# AST1080 register map
File version: 1.0
CPU: CM4 r0p1, little endian, MPU, FPU, 4 interrupt priority bits, 256 interrupts
Registers are 32-bit, read-write, reset 0x0 unless marked. A register's access mark holds for its fields unless they carry their own. Offsets are from the block's base; [hi:lo] are bit positions; {n}, {i} and the like mark numbered series; 'fields as' and 'values as' point back to an identical list.

## gpio (part 1 of 2)
Base 0x74C0B000
0x00 GPIO000 — Debounce Timer Setting Register \#1
  [23:0] DebounceTimerValue
0x04 GPIO004 — Debounce Timer Setting Register \#2
  [23:0] DebounceTimerValue1 — Debounce Timer Value
0x08 GPIO008 — Debounce Timer Setting Register \#3
  [23:0] DebounceTimerValue2 — Debounce Timer Value
0x0C GPIO00C — GPIO Blink Source Clock Division
  [23:0] BlinkSourceClkDivisionOnlyEffectiveToPCLKAsSrcClk — Blink Source Clock Division. Only effective to PCLK as source clock
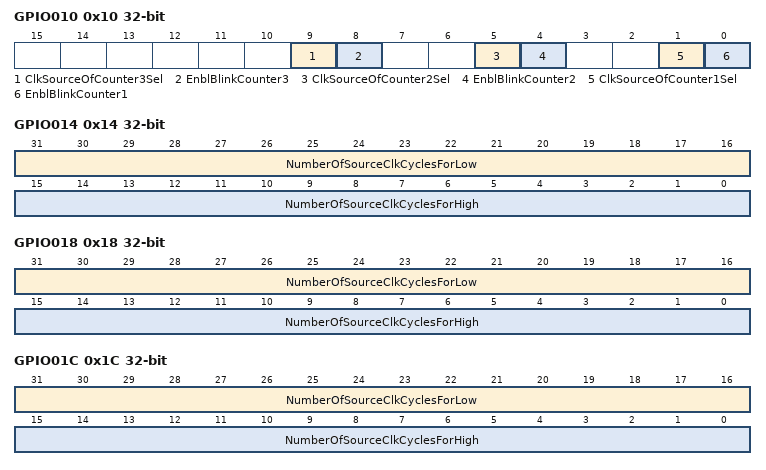
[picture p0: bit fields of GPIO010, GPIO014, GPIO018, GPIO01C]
0x10 GPIO010 — GPIO Blink Control
  [9] ClkSourceOfCounter3Sel — Clock Source of Counter #3 Selection
    0=Choose_PCLKhlinkGPIO00C1_As_Source_Clock; 1=Choose_CLK1M_As_Source_Clock
  [8] EnblBlinkCounter3 — Enable Blink Counter #3
  [5] ClkSourceOfCounter2Sel — Clock Source of Counter #2 Selection
    values as ClkSourceOfCounter3Sel
  [4] EnblBlinkCounter2 — Enable Blink Counter #2
  [1] ClkSourceOfCounter1Sel — Clock Source of Counter #1 Selection
    values as ClkSourceOfCounter3Sel
  [0] EnblBlinkCounter1 — Enable Blink Counter #1
0x14 GPIO014 — GPIO Blink Counter \#1 Configuration
  [31:16] NumberOfSourceClkCyclesForLow — Number of Source Clock cycles for Low
  [15:0] NumberOfSourceClkCyclesForHigh — Number of Source Clock cycles for High
0x18 GPIO018 — GPIO Blink Counter \#2 Configuration
  fields as GPIO014
0x1C GPIO01C — GPIO Blink Counter \#3 Configuration
  fields as GPIO014
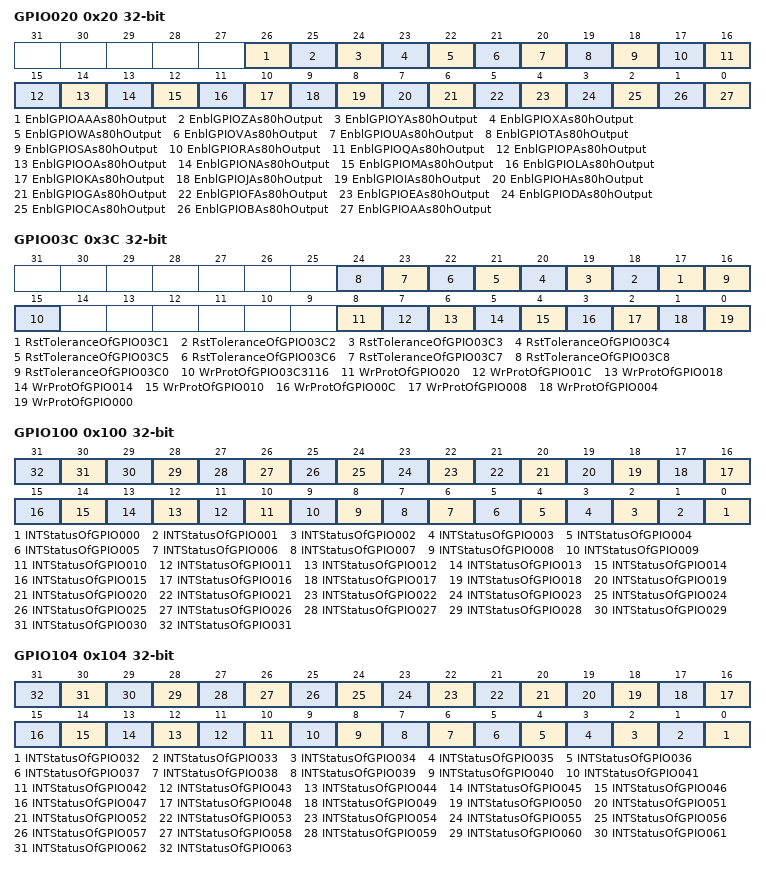
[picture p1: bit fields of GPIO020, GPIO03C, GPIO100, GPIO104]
0x20 GPIO020 — 80h Enable Register
  [26] EnblGPIOAAAs80hOutput — Enable GPIOAA as 80h output
  [25] EnblGPIOZAs80hOutput — Enable GPIOZ as 80h output
  [24] EnblGPIOYAs80hOutput — Enable GPIOY as 80h output
  [23] EnblGPIOXAs80hOutput — Enable GPIOX as 80h output
  [22] EnblGPIOWAs80hOutput — Enable GPIOW as 80h output
  [21] EnblGPIOVAs80hOutput — Enable GPIOV as 80h output
  [20] EnblGPIOUAs80hOutput — Enable GPIOU as 80h output
  [19] EnblGPIOTAs80hOutput — Enable GPIOT as 80h output
  [18] EnblGPIOSAs80hOutput — Enable GPIOS as 80h output
  [17] EnblGPIORAs80hOutput — Enable GPIOR as 80h output
  [16] EnblGPIOQAs80hOutput — Enable GPIOQ as 80h output
  [15] EnblGPIOPAs80hOutput — Enable GPIOP as 80h output
  [14] EnblGPIOOAs80hOutput — Enable GPIOO as 80h output
  [13] EnblGPIONAs80hOutput — Enable GPION as 80h output
  [12] EnblGPIOMAs80hOutput — Enable GPIOM as 80h output
  [11] EnblGPIOLAs80hOutput — Enable GPIOL as 80h output
  [10] EnblGPIOKAs80hOutput — Enable GPIOK as 80h output
  [9] EnblGPIOJAs80hOutput — Enable GPIOJ as 80h output
  [8] EnblGPIOIAs80hOutput — Enable GPIOI as 80h output
  [7] EnblGPIOHAs80hOutput — Enable GPIOH as 80h output
  [6] EnblGPIOGAs80hOutput — Enable GPIOG as 80h output
  [5] EnblGPIOFAs80hOutput — Enable GPIOF as 80h output
  [4] EnblGPIOEAs80hOutput — Enable GPIOE as 80h output
  [3] EnblGPIODAs80hOutput — Enable GPIOD as 80h output
  [2] EnblGPIOCAs80hOutput — Enable GPIOC as 80h output
  [1] EnblGPIOBAs80hOutput — Enable GPIOB as 80h output
  [0] EnblGPIOAAs80hOutput — Enable GPIOA as 80h output
0x3C GPIO03C — Write Protection Register
  [n+16] RstToleranceOfGPIO03C{n} (n=1..8) — Reset Tolerance of GPIO03C[{n}]
  [16] RstToleranceOfGPIO03C0 — Reset Tolerance of GPIO03C[0]
    0=SRST; 1=WDT_Reset
  [15] WrProtOfGPIO03C3116 — Write Protection of GPIO03C[31:16]
  [8] WrProtOfGPIO020 — Write Protection of GPIO020
  [7] WrProtOfGPIO01C — Write Protection of GPIO01C
  [6] WrProtOfGPIO018 — Write Protection of GPIO018
  [5] WrProtOfGPIO014 — Write Protection of GPIO014
  [4] WrProtOfGPIO010 — Write Protection of GPIO010
  [3] WrProtOfGPIO00C — Write Protection of GPIO00C
  [2] WrProtOfGPIO008 — Write Protection of GPIO008
  [1] WrProtOfGPIO004 — Write Protection of GPIO004
  [0] WrProtOfGPIO000 — Write Protection of GPIO000
0x100 GPIO100 — Interrupt Status Register \#1
  [n] INTStatusOfGPIO{n:03} ro (n=0..31) — Interrupt Status of GPIO{n:03}
0x104 GPIO104 — Interrupt Status Register \#2
  [n-32] INTStatusOfGPIO{n:03} ro (n=32..63) — Interrupt Status of GPIO{n:03}
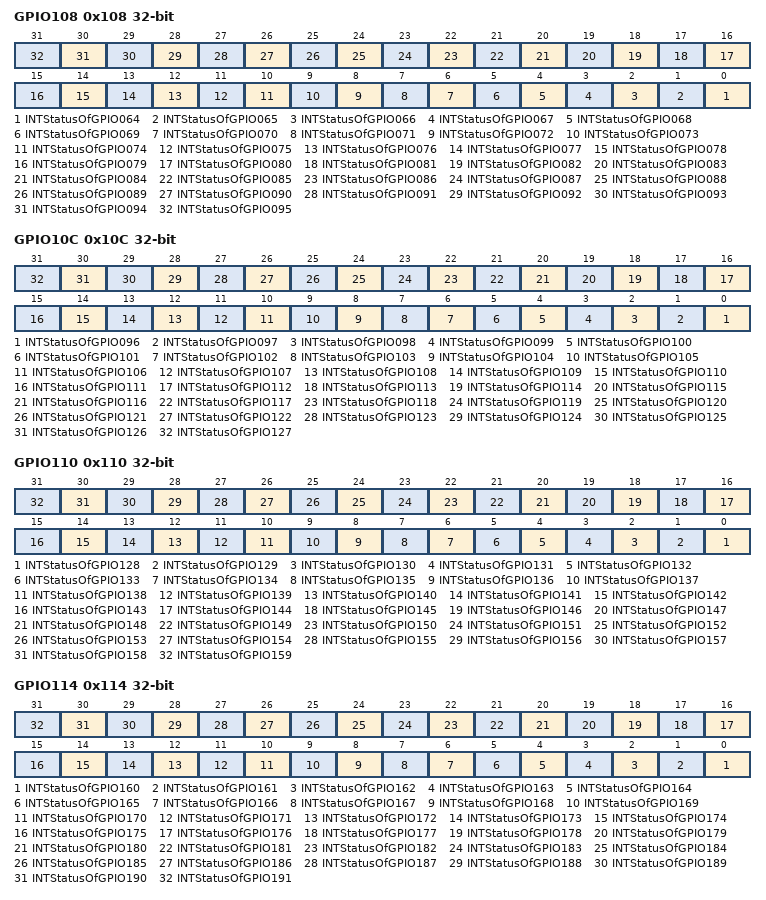
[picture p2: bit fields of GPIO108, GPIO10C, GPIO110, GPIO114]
0x108 GPIO108 — Interrupt Status Register \#3
  [n-64] INTStatusOfGPIO{n:03} ro (n=64..95) — Interrupt Status of GPIO{n:03}
0x10C GPIO10C — Interrupt Status Register \#4
  [n-96] INTStatusOfGPIO{n:03} ro (n=96..127) — Interrupt Status of GPIO{n:03}
0x110 GPIO110 — Interrupt Status Register \#5
  [n-128] INTStatusOfGPIO{n} ro (n=128..159) — Interrupt Status of GPIO{n}
0x114 GPIO114 — Interrupt Status Register \#6
  [n-160] INTStatusOfGPIO{n} ro (n=160..191) — Interrupt Status of GPIO{n}
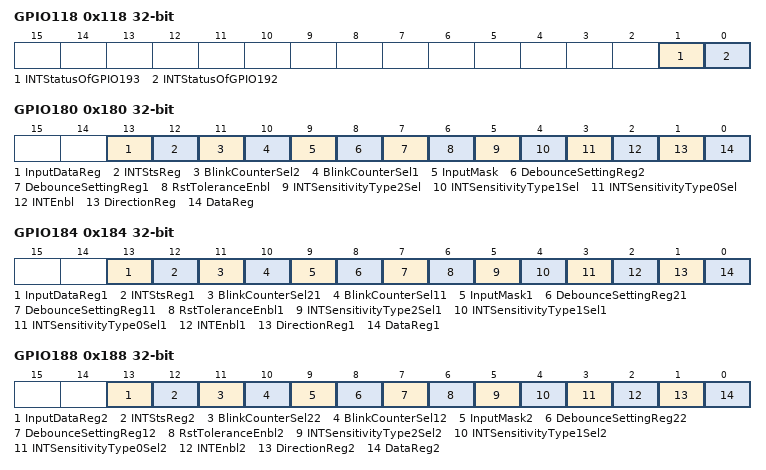
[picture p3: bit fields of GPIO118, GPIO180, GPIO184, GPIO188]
0x118 GPIO118 — Interrupt Status Register \#7
  [1] INTStatusOfGPIO193 ro — Interrupt Status of GPIO193
  [0] INTStatusOfGPIO192 ro — Interrupt Status of GPIO192
0x180 GPIO180 — GPIO000 Control Register
  [13] InputDataReg ro — Input data register
  [12] INTStsReg — Interrupt status register
    0=No_Interrupt_Pending; 1=Interrupt_Pending
  [11] BlinkCounterSel2 — Blink Counter Selection #2
  [10] BlinkCounterSel1 — Blink Counter Selection #1
  [9] InputMask
    0=Read_From_Bit13_Will_Be_Updated; 1=Read_From_Bit13_Will_Not_Be_Updated
  [8] DebounceSettingReg2 — Debounce setting register #2
  [7] DebounceSettingReg1 — Debounce setting register #1
  [6] RstToleranceEnbl — Reset tolerance enable
    0=Bit0_And_Bit1_Will_Be_Reset_By_WDTSOC_Andor_EXTRSTN_Reset; 1=Bit0_And_Bit1_Will_Not_Be_Reset_By_WDTSOC_Andor_EXTRSTN
  [5] INTSensitivityType2Sel — Interrupt sensitivity type 2 selection
    0=Select_Edge_Or_Level_Trigger_Mode; 1=Select_Dualedge_Trigger_Mode
  [4] INTSensitivityType1Sel — Interrupt sensitivity type 1 selection
    0=Select_Edge_Trigger_Mode; 1=Select_Level_Trigger_Mode
  [3] INTSensitivityType0Sel — Interrupt sensitivity type 0 selection
    0=Select_Fallingedge_Or_Levellow_Trigger_Mode; 1=Select_Risingedge_Or_Levelhigh_Trigger_Mode
  [2] INTEnbl — Interrupt enable
    0=Disable_Interrupt; 1=Enable_Interrupt
  [1] DirectionReg — Direction register
    0=Input; 1=Output
  [0] DataReg — Data register
    0=Output_0_If_Bit1_Is_1; 1=Output_1_If_Bit1_Is_1
0x184 GPIO184 — GPIO001 Control Register
  [13] InputDataReg1 ro — Input data register
  [12] INTStsReg1 — Interrupt status register
    0=No_Interrupt_Pending; 1=Interrupt_Pending
  [11] BlinkCounterSel21 — Blink Counter Selection #2
  [10] BlinkCounterSel11 — Blink Counter Selection #1
  [9] InputMask1 — Input mask
    values as GPIO180.InputMask
  [8] DebounceSettingReg21 — Debounce setting register #2
  [7] DebounceSettingReg11 — Debounce setting register #1
  [6] RstToleranceEnbl1 — Reset tolerance enable
    values as GPIO180.RstToleranceEnbl
  [5] INTSensitivityType2Sel1 — Interrupt sensitivity type 2 selection
    values as GPIO180.INTSensitivityType2Sel
  [4] INTSensitivityType1Sel1 — Interrupt sensitivity type 1 selection
    0=Select_Edge_Trigger_Mode; 1=Select_Level_Trigger_Mode
  [3] INTSensitivityType0Sel1 — Interrupt sensitivity type 0 selection
    values as GPIO180.INTSensitivityType0Sel
  [2] INTEnbl1 — Interrupt enable
    0=Disable_Interrupt; 1=Enable_Interrupt
  [1] DirectionReg1 — Direction register
    0=Input; 1=Output
  [0] DataReg1 — Data register
    0=Output_0_If_Bit1_Is_1; 1=Output_1_If_Bit1_Is_1
0x188 GPIO188 — GPIO002 Control Register
  [13] InputDataReg2 ro — Input data register
  [12] INTStsReg2 — Interrupt status register
    0=No_Interrupt_Pending; 1=Interrupt_Pending
  [11] BlinkCounterSel22 — Blink Counter Selection #2
  [10] BlinkCounterSel12 — Blink Counter Selection #1
  [9] InputMask2 — Input mask
    values as GPIO180.InputMask
  [8] DebounceSettingReg22 — Debounce setting register #2
  [7] DebounceSettingReg12 — Debounce setting register #1
  [6] RstToleranceEnbl2 — Reset tolerance enable
    values as GPIO180.RstToleranceEnbl
  [5] INTSensitivityType2Sel2 — Interrupt sensitivity type 2 selection
    values as GPIO180.INTSensitivityType2Sel
  [4] INTSensitivityType1Sel2 — Interrupt sensitivity type 1 selection
    0=Select_Edge_Trigger_Mode; 1=Select_Level_Trigger_Mode
  [3] INTSensitivityType0Sel2 — Interrupt sensitivity type 0 selection
    values as GPIO180.INTSensitivityType0Sel
  [2] INTEnbl2 — Interrupt enable
    0=Disable_Interrupt; 1=Enable_Interrupt
  [1] DirectionReg2 — Direction register
    0=Input; 1=Output
  [0] DataReg2 — Data register
    0=Output_0_If_Bit1_Is_1; 1=Output_1_If_Bit1_Is_1
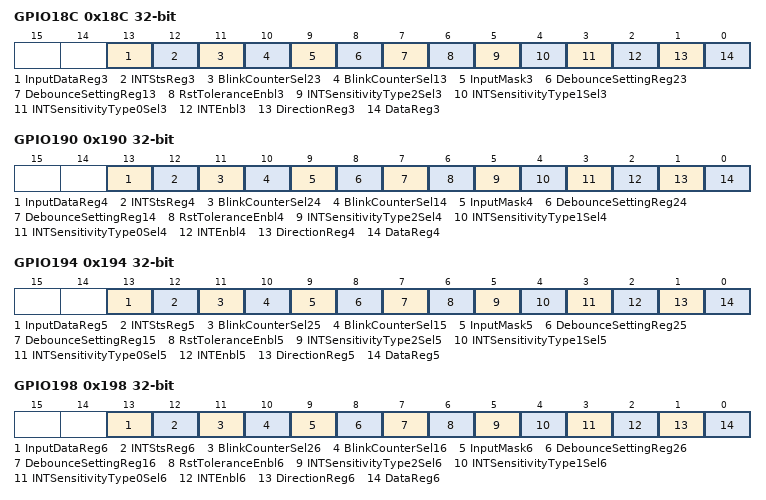
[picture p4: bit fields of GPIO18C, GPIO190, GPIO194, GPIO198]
0x18C GPIO18C — GPIO003 Control Register
  [13] InputDataReg3 ro — Input data register
  [12] INTStsReg3 — Interrupt status register
    0=No_Interrupt_Pending; 1=Interrupt_Pending
  [11] BlinkCounterSel23 — Blink Counter Selection #2
  [10] BlinkCounterSel13 — Blink Counter Selection #1
  [9] InputMask3 — Input mask
    values as GPIO180.InputMask
  [8] DebounceSettingReg23 — Debounce setting register #2
  [7] DebounceSettingReg13 — Debounce setting register #1
  [6] RstToleranceEnbl3 — Reset tolerance enable
    values as GPIO180.RstToleranceEnbl
  [5] INTSensitivityType2Sel3 — Interrupt sensitivity type 2 selection
    values as GPIO180.INTSensitivityType2Sel
  [4] INTSensitivityType1Sel3 — Interrupt sensitivity type 1 selection
    0=Select_Edge_Trigger_Mode; 1=Select_Level_Trigger_Mode
  [3] INTSensitivityType0Sel3 — Interrupt sensitivity type 0 selection
    values as GPIO180.INTSensitivityType0Sel
  [2] INTEnbl3 — Interrupt enable
    0=Disable_Interrupt; 1=Enable_Interrupt
  [1] DirectionReg3 — Direction register
    0=Input; 1=Output
  [0] DataReg3 — Data register
    0=Output_0_If_Bit1_Is_1; 1=Output_1_If_Bit1_Is_1
0x190 GPIO190 — GPIO004 Control Register
  [13] InputDataReg4 ro — Input data register
  [12] INTStsReg4 — Interrupt status register
    0=No_Interrupt_Pending; 1=Interrupt_Pending
  [11] BlinkCounterSel24 — Blink Counter Selection #2
  [10] BlinkCounterSel14 — Blink Counter Selection #1
  [9] InputMask4 — Input mask
    values as GPIO180.InputMask
  [8] DebounceSettingReg24 — Debounce setting register #2
  [7] DebounceSettingReg14 — Debounce setting register #1
  [6] RstToleranceEnbl4 — Reset tolerance enable
    values as GPIO180.RstToleranceEnbl
  [5] INTSensitivityType2Sel4 — Interrupt sensitivity type 2 selection
    values as GPIO180.INTSensitivityType2Sel
  [4] INTSensitivityType1Sel4 — Interrupt sensitivity type 1 selection
    0=Select_Edge_Trigger_Mode; 1=Select_Level_Trigger_Mode
  [3] INTSensitivityType0Sel4 — Interrupt sensitivity type 0 selection
    values as GPIO180.INTSensitivityType0Sel
  [2] INTEnbl4 — Interrupt enable
    0=Disable_Interrupt; 1=Enable_Interrupt
  [1] DirectionReg4 — Direction register
    0=Input; 1=Output
  [0] DataReg4 — Data register
    0=Output_0_If_Bit1_Is_1; 1=Output_1_If_Bit1_Is_1
0x194 GPIO194 — GPIO005 Control Register
  [13] InputDataReg5 ro — Input data register
  [12] INTStsReg5 — Interrupt status register
    0=No_Interrupt_Pending; 1=Interrupt_Pending
  [11] BlinkCounterSel25 — Blink Counter Selection #2
  [10] BlinkCounterSel15 — Blink Counter Selection #1
  [9] InputMask5 — Input mask
    values as GPIO180.InputMask
  [8] DebounceSettingReg25 — Debounce setting register #2
  [7] DebounceSettingReg15 — Debounce setting register #1
  [6] RstToleranceEnbl5 — Reset tolerance enable
    values as GPIO180.RstToleranceEnbl
  [5] INTSensitivityType2Sel5 — Interrupt sensitivity type 2 selection
    values as GPIO180.INTSensitivityType2Sel
  [4] INTSensitivityType1Sel5 — Interrupt sensitivity type 1 selection
    0=Select_Edge_Trigger_Mode; 1=Select_Level_Trigger_Mode
  [3] INTSensitivityType0Sel5 — Interrupt sensitivity type 0 selection
    values as GPIO180.INTSensitivityType0Sel
  [2] INTEnbl5 — Interrupt enable
    0=Disable_Interrupt; 1=Enable_Interrupt
  [1] DirectionReg5 — Direction register
    0=Input; 1=Output
  [0] DataReg5 — Data register
    0=Output_0_If_Bit1_Is_1; 1=Output_1_If_Bit1_Is_1
0x198 GPIO198 — GPIO006 Control Register
  [13] InputDataReg6 ro — Input data register
  [12] INTStsReg6 — Interrupt status register
    0=No_Interrupt_Pending; 1=Interrupt_Pending
  [11] BlinkCounterSel26 — Blink Counter Selection #2
  [10] BlinkCounterSel16 — Blink Counter Selection #1
  [9] InputMask6 — Input mask
    values as GPIO180.InputMask
  [8] DebounceSettingReg26 — Debounce setting register #2
  [7] DebounceSettingReg16 — Debounce setting register #1
  [6] RstToleranceEnbl6 — Reset tolerance enable
    values as GPIO180.RstToleranceEnbl
  [5] INTSensitivityType2Sel6 — Interrupt sensitivity type 2 selection
    values as GPIO180.INTSensitivityType2Sel
  [4] INTSensitivityType1Sel6 — Interrupt sensitivity type 1 selection
    0=Select_Edge_Trigger_Mode; 1=Select_Level_Trigger_Mode
  [3] INTSensitivityType0Sel6 — Interrupt sensitivity type 0 selection
    values as GPIO180.INTSensitivityType0Sel
  [2] INTEnbl6 — Interrupt enable
    0=Disable_Interrupt; 1=Enable_Interrupt
  [1] DirectionReg6 — Direction register
    0=Input; 1=Output
  [0] DataReg6 — Data register
    0=Output_0_If_Bit1_Is_1; 1=Output_1_If_Bit1_Is_1
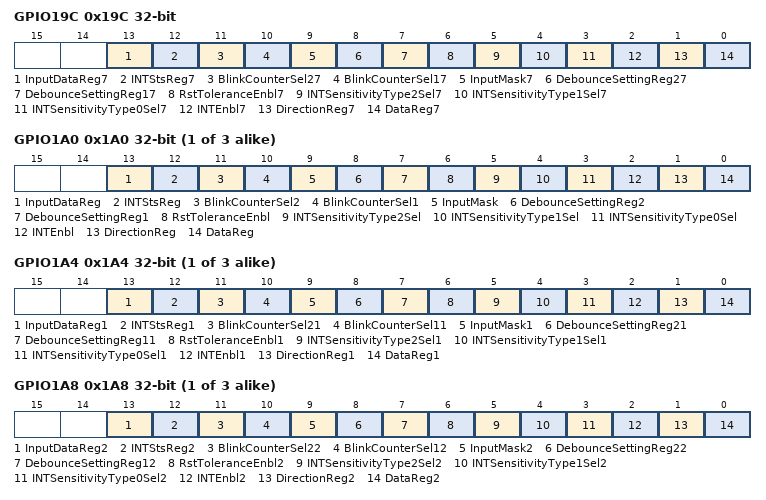
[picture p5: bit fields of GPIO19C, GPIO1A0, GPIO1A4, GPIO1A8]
0x19C GPIO19C — GPIO007 Control Register
  [13] InputDataReg7 ro — Input data register
  [12] INTStsReg7 — Interrupt status register
    0=No_Interrupt_Pending; 1=Interrupt_Pending
  [11] BlinkCounterSel27 — Blink Counter Selection #2
  [10] BlinkCounterSel17 — Blink Counter Selection #1
  [9] InputMask7 — Input mask
    values as GPIO180.InputMask
  [8] DebounceSettingReg27 — Debounce setting register #2
  [7] DebounceSettingReg17 — Debounce setting register #1
  [6] RstToleranceEnbl7 — Reset tolerance enable
    values as GPIO180.RstToleranceEnbl
  [5] INTSensitivityType2Sel7 — Interrupt sensitivity type 2 selection
    values as GPIO180.INTSensitivityType2Sel
  [4] INTSensitivityType1Sel7 — Interrupt sensitivity type 1 selection
    0=Select_Edge_Trigger_Mode; 1=Select_Level_Trigger_Mode
  [3] INTSensitivityType0Sel7 — Interrupt sensitivity type 0 selection
    values as GPIO180.INTSensitivityType0Sel
  [2] INTEnbl7 — Interrupt enable
    0=Disable_Interrupt; 1=Enable_Interrupt
  [1] DirectionReg7 — Direction register
    0=Input; 1=Output
  [0] DataReg7 — Data register
    0=Output_0_If_Bit1_Is_1; 1=Output_1_If_Bit1_Is_1
{0xA0+0x100*i} GPIO{i}A0 (i=1..3) — GPIO{64i-56:03} Control Register
  fields as GPIO180
{0xA4+0x100*i} GPIO{i}A4 (i=1..3) — GPIO{64i-55:03} Control Register
  fields as GPIO184
{0xA8+0x100*i} GPIO{i}A8 (i=1..3) — GPIO{64i-54:03} Control Register
  fields as GPIO188
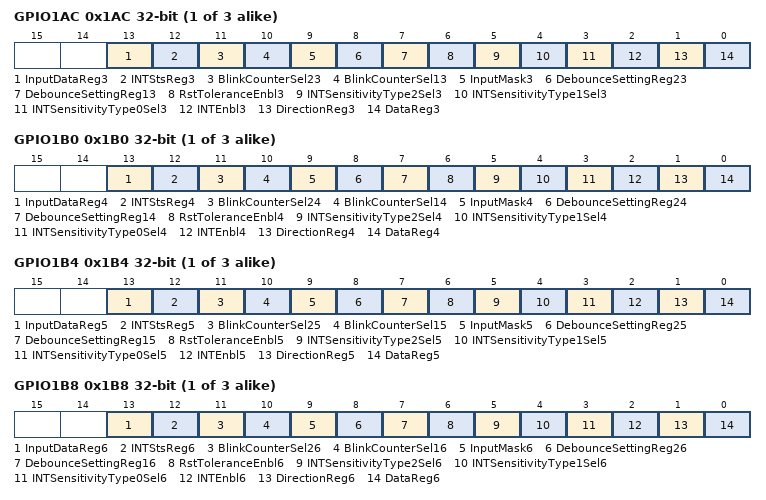
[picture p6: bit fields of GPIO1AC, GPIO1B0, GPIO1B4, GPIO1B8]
{0xAC+0x100*i} GPIO{i}AC (i=1..3) — GPIO{64i-53:03} Control Register
  fields as GPIO18C
{0xB0+0x100*i} GPIO{i}B0 (i=1..3) — GPIO{64i-52:03} Control Register
  fields as GPIO190
{0xB4+0x100*i} GPIO{i}B4 (i=1..3) — GPIO{64i-51:03} Control Register
  fields as GPIO194
{0xB8+0x100*i} GPIO{i}B8 (i=1..3) — GPIO{64i-50:03} Control Register
  fields as GPIO198
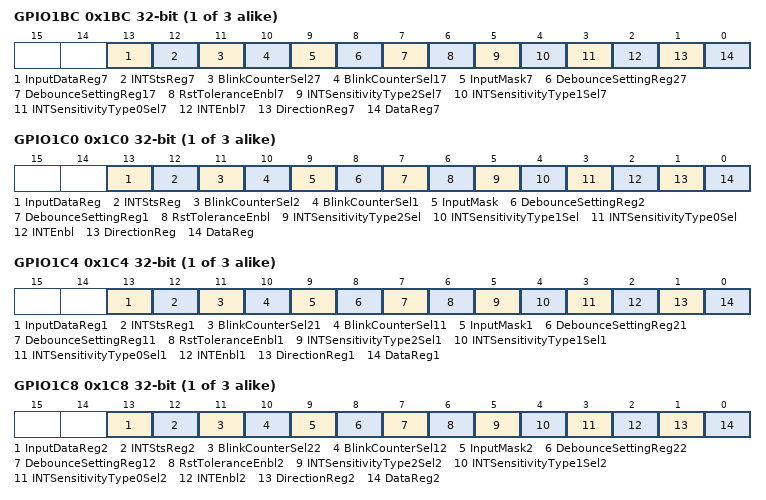
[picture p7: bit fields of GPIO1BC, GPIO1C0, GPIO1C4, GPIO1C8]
{0xBC+0x100*i} GPIO{i}BC (i=1..3) — GPIO{64i-49:03} Control Register
  fields as GPIO19C
{0xC0+0x100*i} GPIO{i}C0 (i=1..3) — GPIO{64i-48:03} Control Register
  fields as GPIO180
{0xC4+0x100*i} GPIO{i}C4 (i=1..3) — GPIO{64i-47:03} Control Register
  fields as GPIO184
{0xC8+0x100*i} GPIO{i}C8 (i=1..3) — GPIO{64i-46:03} Control Register
  fields as GPIO188
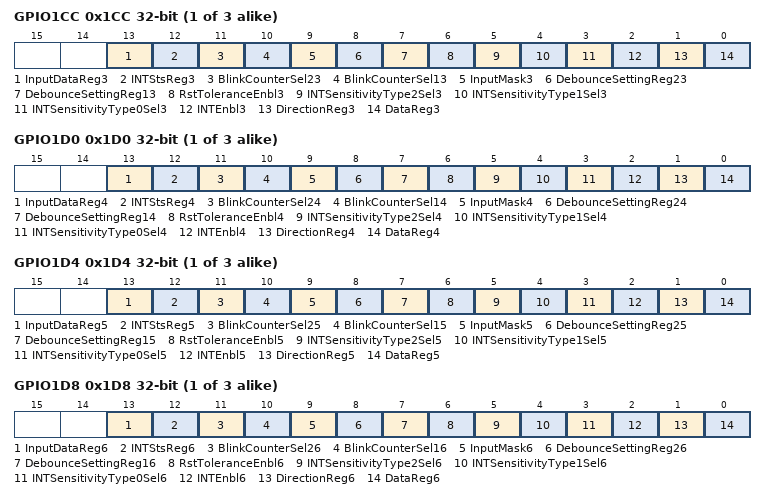
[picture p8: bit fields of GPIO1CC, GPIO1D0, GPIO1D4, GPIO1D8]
{0xCC+0x100*i} GPIO{i}CC (i=1..3) — GPIO{64i-45:03} Control Register
  fields as GPIO18C
{0xD0+0x100*i} GPIO{i}D0 (i=1..3) — GPIO{64i-44:03} Control Register
  fields as GPIO190
{0xD4+0x100*i} GPIO{i}D4 (i=1..3) — GPIO{64i-43:03} Control Register
  fields as GPIO194
{0xD8+0x100*i} GPIO{i}D8 (i=1..3) — GPIO{64i-42:03} Control Register
  fields as GPIO198
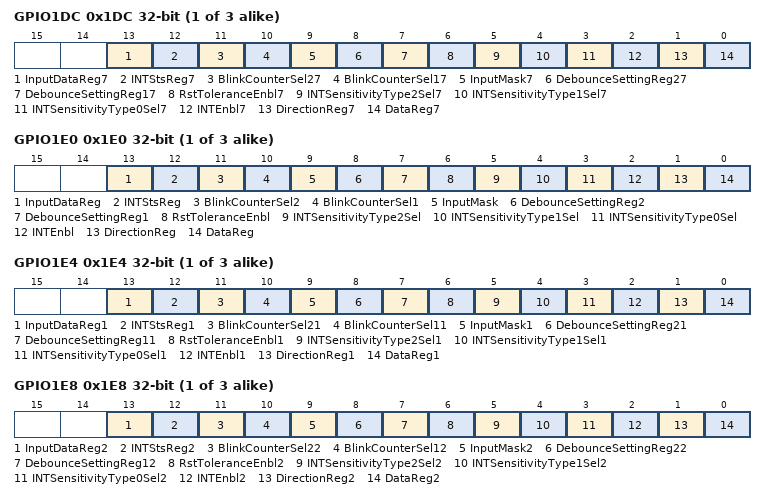
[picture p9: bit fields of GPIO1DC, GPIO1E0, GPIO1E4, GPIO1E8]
{0xDC+0x100*i} GPIO{i}DC (i=1..3) — GPIO{64i-41:03} Control Register
  fields as GPIO19C
{0xE0+0x100*i} GPIO{i}E0 (i=1..3) — GPIO{64i-40:03} Control Register
  fields as GPIO180
{0xE4+0x100*i} GPIO{i}E4 (i=1..3) — GPIO{64i-39:03} Control Register
  fields as GPIO184
{0xE8+0x100*i} GPIO{i}E8 (i=1..3) — GPIO{64i-38:03} Control Register
  fields as GPIO188
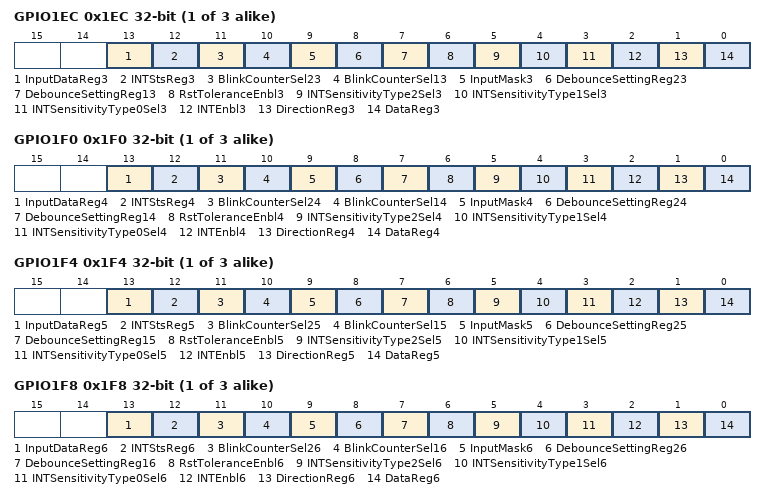
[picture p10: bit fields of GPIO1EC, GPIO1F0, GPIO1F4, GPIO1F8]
{0xEC+0x100*i} GPIO{i}EC (i=1..3) — GPIO{64i-37:03} Control Register
  fields as GPIO18C
{0xF0+0x100*i} GPIO{i}F0 (i=1..3) — GPIO{64i-36:03} Control Register
  fields as GPIO190
{0xF4+0x100*i} GPIO{i}F4 (i=1..3) — GPIO{64i-35:03} Control Register
  fields as GPIO194
{0xF8+0x100*i} GPIO{i}F8 (i=1..3) — GPIO{64i-34:03} Control Register
  fields as GPIO198
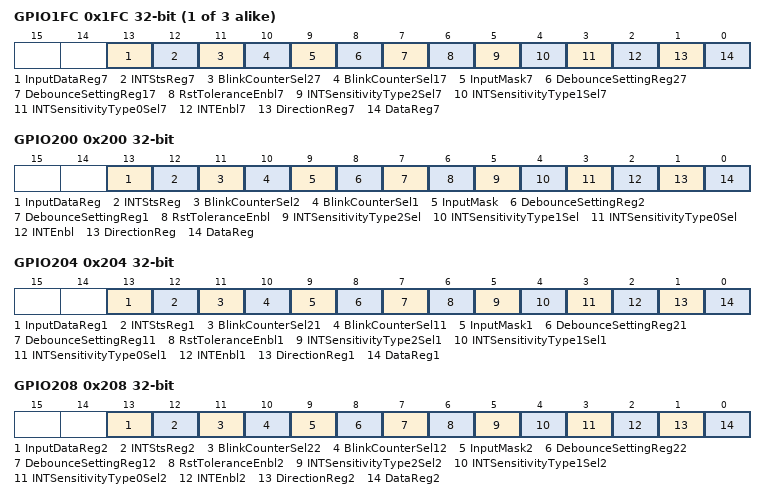
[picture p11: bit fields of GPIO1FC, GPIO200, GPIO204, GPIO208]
{0xFC+0x100*i} GPIO{i}FC (i=1..3) — GPIO{64i-33:03} Control Register
  fields as GPIO19C
0x200 GPIO200 — GPIO032 Control Register
  fields as GPIO180
0x204 GPIO204 — GPIO033 Control Register
  fields as GPIO184
0x208 GPIO208 — GPIO034 Control Register
  fields as GPIO188
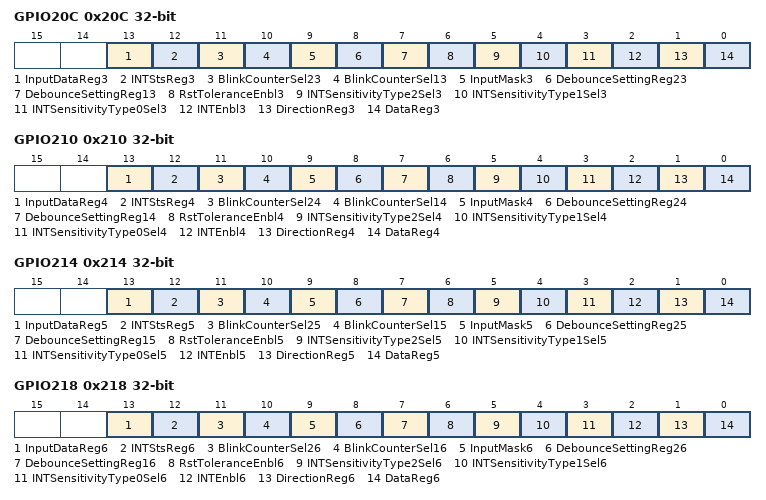
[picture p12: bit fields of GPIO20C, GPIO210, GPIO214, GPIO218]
0x20C GPIO20C — GPIO035 Control Register
  fields as GPIO18C
0x210 GPIO210 — GPIO036 Control Register
  fields as GPIO190
0x214 GPIO214 — GPIO037 Control Register
  fields as GPIO194
0x218 GPIO218 — GPIO038 Control Register
  fields as GPIO198
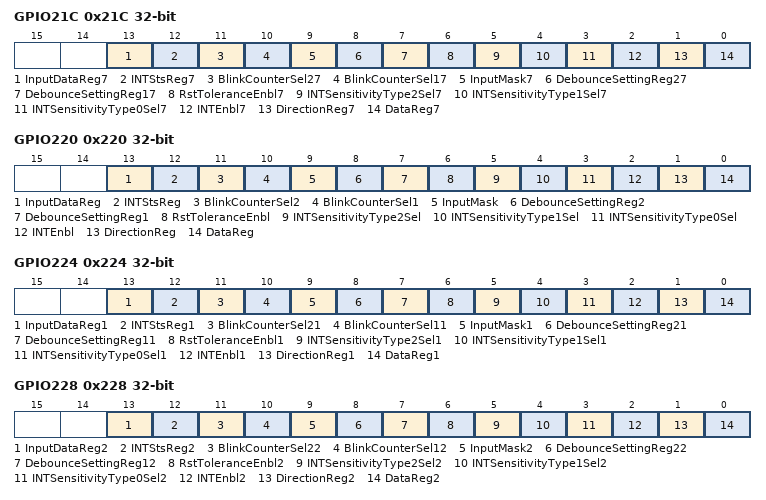
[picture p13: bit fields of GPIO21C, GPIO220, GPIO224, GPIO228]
0x21C GPIO21C — GPIO039 Control Register
  fields as GPIO19C
0x220 GPIO220 — GPIO040 Control Register
  fields as GPIO180
0x224 GPIO224 — GPIO041 Control Register
  fields as GPIO184
0x228 GPIO228 — GPIO042 Control Register
  fields as GPIO188
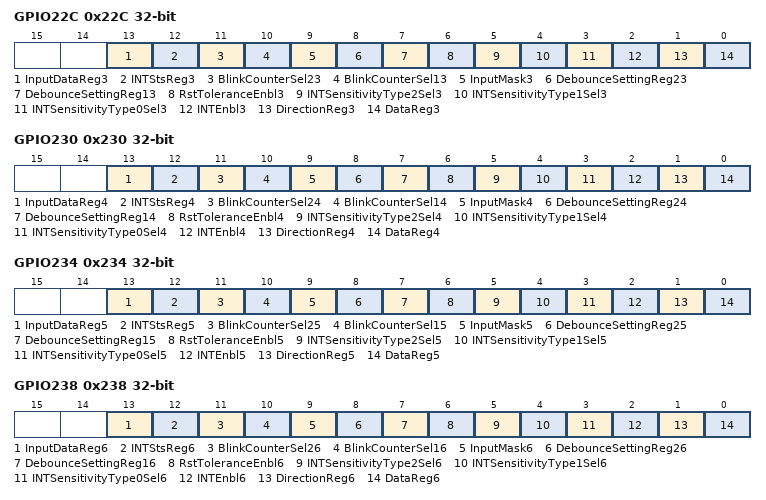
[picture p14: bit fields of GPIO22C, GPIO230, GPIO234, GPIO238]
0x22C GPIO22C — GPIO043 Control Register
  fields as GPIO18C
0x230 GPIO230 — GPIO044 Control Register
  fields as GPIO190
0x234 GPIO234 — GPIO045 Control Register
  fields as GPIO194
0x238 GPIO238 — GPIO046 Control Register
  fields as GPIO198
0x23C GPIO23C — GPIO047 Control Register
  fields as GPIO19C
0x240 GPIO240 — GPIO048 Control Register
  fields as GPIO180
0x244 GPIO244 — GPIO049 Control Register
  fields as GPIO184
0x248 GPIO248 — GPIO050 Control Register
  fields as GPIO188
0x24C GPIO24C — GPIO051 Control Register
  fields as GPIO18C
0x250 GPIO250 — GPIO052 Control Register
  fields as GPIO190
0x254 GPIO254 — GPIO053 Control Register
  fields as GPIO194
0x258 GPIO258 — GPIO054 Control Register
  fields as GPIO198
0x25C GPIO25C — GPIO055 Control Register
  fields as GPIO19C
0x260 GPIO260 — GPIO056 Control Register
  fields as GPIO180
0x264 GPIO264 — GPIO057 Control Register
  fields as GPIO184
0x268 GPIO268 — GPIO058 Control Register
  fields as GPIO188
0x26C GPIO26C — GPIO059 Control Register
  fields as GPIO18C
0x270 GPIO270 — GPIO060 Control Register
  fields as GPIO190
0x274 GPIO274 — GPIO061 Control Register
  fields as GPIO194
0x278 GPIO278 — GPIO062 Control Register
  fields as GPIO198
0x27C GPIO27C — GPIO063 Control Register
  fields as GPIO19C
0x280 GPIO280 — GPIO064 Control Register
  fields as GPIO180
0x284 GPIO284 — GPIO065 Control Register
  fields as GPIO184
0x288 GPIO288 — GPIO066 Control Register
  fields as GPIO188
0x28C GPIO28C — GPIO067 Control Register
  fields as GPIO18C
0x290 GPIO290 — GPIO068 Control Register
  fields as GPIO190
0x294 GPIO294 — GPIO069 Control Register
  fields as GPIO194
0x298 GPIO298 — GPIO070 Control Register
  fields as GPIO198
0x29C GPIO29C — GPIO071 Control Register
  fields as GPIO19C
0x300 GPIO300 — GPIO096 Control Register
  fields as GPIO180
0x304 GPIO304 — GPIO097 Control Register
  fields as GPIO184
0x308 GPIO308 — GPIO098 Control Register
  fields as GPIO188
0x30C GPIO30C — GPIO099 Control Register
  fields as GPIO18C
0x310 GPIO310 — GPIO100 Control Register
  fields as GPIO190
0x314 GPIO314 — GPIO101 Control Register
  fields as GPIO194
0x318 GPIO318 — GPIO102 Control Register
  fields as GPIO198
0x31C GPIO31C — GPIO103 Control Register
  fields as GPIO19C
0x320 GPIO320 — GPIO104 Control Register
  fields as GPIO180
0x324 GPIO324 — GPIO105 Control Register
  fields as GPIO184
0x328 GPIO328 — GPIO106 Control Register
  fields as GPIO188
0x32C GPIO32C — GPIO107 Control Register
  fields as GPIO18C
0x330 GPIO330 — GPIO108 Control Register
  fields as GPIO190
0x334 GPIO334 — GPIO109 Control Register
  fields as GPIO194
0x338 GPIO338 — GPIO110 Control Register
  fields as GPIO198
0x33C GPIO33C — GPIO111 Control Register
  fields as GPIO19C
0x340 GPIO340 — GPIO112 Control Register
  fields as GPIO180
0x344 GPIO344 — GPIO113 Control Register
  fields as GPIO184
0x348 GPIO348 — GPIO114 Control Register
  fields as GPIO188
0x34C GPIO34C — GPIO115 Control Register
  fields as GPIO18C
0x350 GPIO350 — GPIO116 Control Register
  fields as GPIO190
0x354 GPIO354 — GPIO117 Control Register
  fields as GPIO194
0x358 GPIO358 — GPIO118 Control Register
  fields as GPIO198
0x35C GPIO35C — GPIO119 Control Register
  fields as GPIO19C
0x360 GPIO360 — GPIO120 Control Register
  fields as GPIO180
0x364 GPIO364 — GPIO121 Control Register
  fields as GPIO184
0x368 GPIO368 — GPIO122 Control Register
  fields as GPIO188
0x36C GPIO36C — GPIO123 Control Register
  fields as GPIO18C
0x370 GPIO370 — GPIO124 Control Register
  fields as GPIO190
0x374 GPIO374 — GPIO125 Control Register
  fields as GPIO194
0x378 GPIO378 — GPIO126 Control Register
  fields as GPIO198
0x37C GPIO37C — GPIO127 Control Register
  fields as GPIO19C
0x380 GPIO380 — GPIO128 Control Register
  fields as GPIO180
0x384 GPIO384 — GPIO129 Control Register
  fields as GPIO184
0x388 GPIO388 — GPIO130 Control Register
  fields as GPIO188
0x38C GPIO38C — GPIO131 Control Register
  fields as GPIO18C
0x390 GPIO390 — GPIO132 Control Register
  fields as GPIO190
0x394 GPIO394 — GPIO133 Control Register
  fields as GPIO194
0x398 GPIO398 — GPIO134 Control Register
  fields as GPIO198
0x39C GPIO39C — GPIO135 Control Register
  fields as GPIO19C
0x400 GPIO400 — GPIO160 Control Register
  fields as GPIO180
0x404 GPIO404 — GPIO161 Control Register
  fields as GPIO184
0x408 GPIO408 — GPIO162 Control Register
  fields as GPIO188
0x40C GPIO40C — GPIO163 Control Register
  fields as GPIO18C
0x410 GPIO410 — GPIO164 Control Register
  fields as GPIO190
0x414 GPIO414 — GPIO165 Control Register
  fields as GPIO194
0x418 GPIO418 — GPIO166 Control Register
  fields as GPIO198
0x41C GPIO41C — GPIO167 Control Register
  fields as GPIO19C
0x420 GPIO420 — GPIO168 Control Register
  fields as GPIO180
0x424 GPIO424 — GPIO169 Control Register
  fields as GPIO184
0x428 GPIO428 — GPIO170 Control Register
  fields as GPIO188
0x42C GPIO42C — GPIO171 Control Register
  fields as GPIO18C
0x430 GPIO430 — GPIO172 Control Register
  fields as GPIO190
0x434 GPIO434 — GPIO173 Control Register
  fields as GPIO194
0x438 GPIO438 — GPIO174 Control Register
  fields as GPIO198
0x43C GPIO43C — GPIO175 Control Register
  fields as GPIO19C
0x440 GPIO440 — GPIO176 Control Register
  fields as GPIO180
0x444 GPIO444 — GPIO177 Control Register
  fields as GPIO184
0x448 GPIO448 — GPIO178 Control Register
  fields as GPIO188
0x44C GPIO44C — GPIO179 Control Register
  fields as GPIO18C
0x450 GPIO450 — GPIO180 Control Register
  fields as GPIO190
0x454 GPIO454 — GPIO181 Control Register
  fields as GPIO194
0x458 GPIO458 — GPIO182 Control Register
  fields as GPIO198
0x45C GPIO45C — GPIO183 Control Register
  fields as GPIO19C
0x460 GPIO460 — GPIO184 Control Register
  fields as GPIO180
0x464 GPIO464 — GPIO185 Control Register
  fields as GPIO184
0x468 GPIO468 — GPIO186 Control Register
  fields as GPIO188
0x46C GPIO46C — GPIO187 Control Register
  fields as GPIO18C
0x470 GPIO470 — GPIO188 Control Register
  fields as GPIO190
0x474 GPIO474 — GPIO189 Control Register
  fields as GPIO194
0x478 GPIO478 — GPIO190 Control Register
  fields as GPIO198
0x47C GPIO47C — GPIO191 Control Register
  fields as GPIO19C
0x480 GPIO480 — GPIO192 Control Register
  fields as GPIO180
0x484 GPIO484 — GPIO193 Control Register
  fields as GPIO184
0x800 GPIO800 reset 0x3F3F3F3F — Master Control Register \#1
  [8n+7] SecMaster{n} (n=0..3) — Secure Master #{n}
    1=Secure; 0=NonSecure
  [8n+6:8n] Master{n}ID (n=0..3)
0x804 GPIO804 reset 0x3F3F3F3F — Master Control Register \#2
  [31] WrProtOfGPIO800AndGPIO804 — Write Protection of GPIO800 and GPIO804
  [23] SecMaster6 — Secure Master #6
    1=Secure; 0=NonSecure
  [22:16] Master6ID
  [15] SecMaster5 — Secure Master #5
    1=Secure; 0=NonSecure
  [14:8] Master5ID
  [7] SecMaster4 — Secure Master #4
    1=Secure; 0=NonSecure
  [6:0] Master4ID
0x808 GPIO808 reset 0xFFFF — GPIO Global Privilege Control Register
  [25] ReadPrivilegeWrProt — Read Privilege Write Protection
  [24] WrPrivilegeWriteProt — Write Privilege Write Protection
  [15:8] ReadPrivilegeOfMaster
  [7:0] WrPrivilegeOfMaster — Write Privilege of Master
0x810 GPIO810 reset 0xFFFFFFFF — GPIO Write Privilege Control Register \#0
  [8n+7:8n] GPIO{n:03}WrPrivilegeOfMaster (n=0..3) — GPIO{n:03} Write Privilege of Master
0x814 GPIO814 reset 0xFFFFFFFF — GPIO Write Privilege Control Register \#1
  [8n-25:8n-32] GPIO{n:03}WrPrivilegeOfMaster (n=4..7) — GPIO{n:03} Write Privilege of Master
0x818 GPIO818 reset 0xFFFFFFFF — GPIO Write Privilege Control Register \#2
  [8n-57:8n-64] GPIO{n:03}WrPrivilegeOfMaster (n=8..11) — GPIO{n:03} Write Privilege of Master
0x81C GPIO81C reset 0xFFFFFFFF — GPIO Write Privilege Control Register \#3
  [8n-89:8n-96] GPIO{n:03}WrPrivilegeOfMaster (n=12..15) — GPIO{n:03} Write Privilege of Master
0x820 GPIO820 reset 0xFFFFFFFF — GPIO Write Privilege Control Register \#4
  [8n-121:8n-128] GPIO{n:03}WrPrivilegeOfMaster (n=16..19) — GPIO{n:03} Write Privilege of Master
0x824 GPIO824 reset 0xFFFFFFFF — GPIO Write Privilege Control Register \#5
  [8n-153:8n-160] GPIO{n:03}WrPrivilegeOfMaster (n=20..23) — GPIO{n:03} Write Privilege of Master
0x828 GPIO828 reset 0xFFFFFFFF — GPIO Write Privilege Control Register \#6
  [8n-185:8n-192] GPIO{n:03}WrPrivilegeOfMaster (n=24..27) — GPIO{n:03} Write Privilege of Master
0x82C GPIO82C reset 0xFFFFFFFF — GPIO Write Privilege Control Register \#7
  [8n-217:8n-224] GPIO{n:03}WrPrivilegeOfMaster (n=28..31) — GPIO{n:03} Write Privilege of Master
0x830 GPIO830 reset 0xFFFFFFFF — GPIO Write Privilege Control Register \#8
  [8n-249:8n-256] GPIO{n:03}WrPrivilegeOfMaster (n=32..35) — GPIO{n:03} Write Privilege of Master
0x834 GPIO834 reset 0xFFFFFFFF — GPIO Write Privilege Control Register \#9
  [8n-281:8n-288] GPIO{n:03}WrPrivilegeOfMaster (n=36..39) — GPIO{n:03} Write Privilege of Master
0x838 GPIO838 reset 0xFFFFFFFF — GPIO Write Privilege Control Register \#10
  [8n-313:8n-320] GPIO{n:03}WrPrivilegeOfMaster (n=40..43) — GPIO{n:03} Write Privilege of Master
0x83C GPIO83C reset 0xFFFFFFFF — GPIO Write Privilege Control Register \#11
  [8n-345:8n-352] GPIO{n:03}WrPrivilegeOfMaster (n=44..47) — GPIO{n:03} Write Privilege of Master
0x840 GPIO840 reset 0xFFFFFFFF — GPIO Write Privilege Control Register \#12
  [8n-377:8n-384] GPIO{n:03}WrPrivilegeOfMaster (n=48..51) — GPIO{n:03} Write Privilege of Master
0x844 GPIO844 reset 0xFFFFFFFF — GPIO Write Privilege Control Register \#13
  [8n-409:8n-416] GPIO{n:03}WrPrivilegeOfMaster (n=52..55) — GPIO{n:03} Write Privilege of Master
0x848 GPIO848 reset 0xFFFFFFFF — GPIO Write Privilege Control Register \#14
  [8n-441:8n-448] GPIO{n:03}WrPrivilegeOfMaster (n=56..59) — GPIO{n:03} Write Privilege of Master
0x84C GPIO84C reset 0xFFFFFFFF — GPIO Write Privilege Control Register \#15
  [8n-473:8n-480] GPIO{n:03}WrPrivilegeOfMaster (n=60..63) — GPIO{n:03} Write Privilege of Master
0x850 GPIO850 reset 0xFFFFFFFF — GPIO Write Privilege Control Register \#16
  [8n-505:8n-512] GPIO{n:03}WrPrivilegeOfMaster (n=64..67) — GPIO{n:03} Write Privilege of Master
0x854 GPIO854 reset 0xFFFFFFFF — GPIO Write Privilege Control Register \#17
  [8n-537:8n-544] GPIO{n:03}WrPrivilegeOfMaster (n=68..71) — GPIO{n:03} Write Privilege of Master
0x858 GPIO858 reset 0xFFFFFFFF — GPIO Write Privilege Control Register \#18
  [8n-569:8n-576] GPIO{n:03}WrPrivilegeOfMaster (n=72..75) — GPIO{n:03} Write Privilege of Master
0x85C GPIO85C reset 0xFFFFFFFF — GPIO Write Privilege Control Register \#19
  [8n-601:8n-608] GPIO{n:03}WrPrivilegeOfMaster (n=76..79) — GPIO{n:03} Write Privilege of Master
0x860 GPIO860 reset 0xFFFFFFFF — GPIO Write Privilege Control Register \#20
  [8n-633:8n-640] GPIO{n:03}WrPrivilegeOfMaster (n=80..83) — GPIO{n:03} Write Privilege of Master
0x864 GPIO864 reset 0xFFFFFFFF — GPIO Write Privilege Control Register \#21
  [8n-665:8n-672] GPIO{n:03}WrPrivilegeOfMaster (n=84..87) — GPIO{n:03} Write Privilege of Master
0x868 GPIO868 reset 0xFFFFFFFF — GPIO Write Privilege Control Register \#22
  [8n-697:8n-704] GPIO{n:03}WrPrivilegeOfMaster (n=88..91) — GPIO{n:03} Write Privilege of Master
0x86C GPIO86C reset 0xFFFFFFFF — GPIO Write Privilege Control Register \#23
  [8n-729:8n-736] GPIO{n:03}WrPrivilegeOfMaster (n=92..95) — GPIO{n:03} Write Privilege of Master
0x870 GPIO870 reset 0xFFFFFFFF — GPIO Write Privilege Control Register \#24
  [8n-761:8n-768] GPIO{n:03}WrPrivilegeOfMaster (n=96..99) — GPIO{n:03} Write Privilege of Master
0x874 GPIO874 reset 0xFFFFFFFF — GPIO Write Privilege Control Register \#25
  [8n-793:8n-800] GPIO{n}WrPrivilegeOfMaster (n=100..103) — GPIO{n} Write Privilege of Master
0x878 GPIO878 reset 0xFFFFFFFF — GPIO Write Privilege Control Register \#26
  [8n-825:8n-832] GPIO{n}WrPrivilegeOfMaster (n=104..107) — GPIO{n} Write Privilege of Master
0x87C GPIO87C reset 0xFFFFFFFF — GPIO Write Privilege Control Register \#27
  [8n-857:8n-864] GPIO{n}WrPrivilegeOfMaster (n=108..111) — GPIO{n} Write Privilege of Master
0x880 GPIO880 reset 0xFFFFFFFF — GPIO Write Privilege Control Register \#28
  [8n-889:8n-896] GPIO{n}WrPrivilegeOfMaster (n=112..115) — GPIO{n} Write Privilege of Master
0x884 GPIO884 reset 0xFFFFFFFF — GPIO Write Privilege Control Register \#29
  [8n-921:8n-928] GPIO{n}WrPrivilegeOfMaster (n=116..119) — GPIO{n} Write Privilege of Master
0x888 GPIO888 reset 0xFFFFFFFF — GPIO Write Privilege Control Register \#30
  [8n-953:8n-960] GPIO{n}WrPrivilegeOfMaster (n=120..123) — GPIO{n} Write Privilege of Master
0x88C GPIO88C reset 0xFFFFFFFF — GPIO Write Privilege Control Register \#31
  [8n-985:8n-992] GPIO{n}WrPrivilegeOfMaster (n=124..127) — GPIO{n} Write Privilege of Master
0x890 GPIO890 reset 0xFFFFFFFF — GPIO Write Privilege Control Register \#32
  [8n-1017:8n-1024] GPIO{n}WrPrivilegeOfMaster (n=128..131) — GPIO{n} Write Privilege of Master
0x894 GPIO894 reset 0xFFFFFFFF — GPIO Write Privilege Control Register \#33
  [8n-1049:8n-1056] GPIO{n}WrPrivilegeOfMaster (n=132..135) — GPIO{n} Write Privilege of Master
0x898 GPIO898 reset 0xFFFFFFFF — GPIO Write Privilege Control Register \#34
  [8n-1081:8n-1088] GPIO{n}WrPrivilegeOfMaster (n=136..139) — GPIO{n} Write Privilege of Master
0x89C GPIO89C reset 0xFFFFFFFF — GPIO Write Privilege Control Register \#35
  [8n-1113:8n-1120] GPIO{n}WrPrivilegeOfMaster (n=140..143) — GPIO{n} Write Privilege of Master
0x8A0 GPIO8A0 reset 0xFFFFFFFF — GPIO Write Privilege Control Register \#36
  [8n-1145:8n-1152] GPIO{n}WrPrivilegeOfMaster (n=144..147) — GPIO{n} Write Privilege of Master
0x8A4 GPIO8A4 reset 0xFFFFFFFF — GPIO Write Privilege Control Register \#37
  [8n-1177:8n-1184] GPIO{n}WrPrivilegeOfMaster (n=148..151) — GPIO{n} Write Privilege of Master
0x8A8 GPIO8A8 reset 0xFFFFFFFF — GPIO Write Privilege Control Register \#38
  [8n-1209:8n-1216] GPIO{n}WrPrivilegeOfMaster (n=152..155) — GPIO{n} Write Privilege of Master
0x8AC GPIO8AC reset 0xFFFFFFFF — GPIO Write Privilege Control Register \#39
  [8n-1241:8n-1248] GPIO{n}WrPrivilegeOfMaster (n=156..159) — GPIO{n} Write Privilege of Master
0x8B0 GPIO8B0 reset 0xFFFFFFFF — GPIO Write Privilege Control Register \#40
  [8n-1273:8n-1280] GPIO{n}WrPrivilegeOfMaster (n=160..163) — GPIO{n} Write Privilege of Master
0x8B4 GPIO8B4 reset 0xFFFFFFFF — GPIO Write Privilege Control Register \#41
  [8n-1305:8n-1312] GPIO{n}WrPrivilegeOfMaster (n=164..167) — GPIO{n} Write Privilege of Master
0x8B8 GPIO8B8 reset 0xFFFFFFFF — GPIO Write Privilege Control Register \#42
  [8n-1337:8n-1344] GPIO{n}WrPrivilegeOfMaster (n=168..171) — GPIO{n} Write Privilege of Master
0x8BC GPIO8BC reset 0xFFFFFFFF — GPIO Write Privilege Control Register \#43
  [8n-1369:8n-1376] GPIO{n}WrPrivilegeOfMaster (n=172..175) — GPIO{n} Write Privilege of Master
0x8C0 GPIO8C0 reset 0xFFFFFFFF — GPIO Write Privilege Control Register \#44
  [8n-1401:8n-1408] GPIO{n}WrPrivilegeOfMaster (n=176..179) — GPIO{n} Write Privilege of Master
0x8C4 GPIO8C4 reset 0xFFFFFFFF — GPIO Write Privilege Control Register \#45
  [8n-1433:8n-1440] GPIO{n}WrPrivilegeOfMaster (n=180..183) — GPIO{n} Write Privilege of Master
0x8C8 GPIO8C8 reset 0xFFFFFFFF — GPIO Write Privilege Control Register \#46
  [8n-1465:8n-1472] GPIO{n}WrPrivilegeOfMaster (n=184..187) — GPIO{n} Write Privilege of Master
0x8CC GPIO8CC reset 0xFFFFFFFF — GPIO Write Privilege Control Register \#47
  [8n-1497:8n-1504] GPIO{n}WrPrivilegeOfMaster (n=188..191) — GPIO{n} Write Privilege of Master
0x8D0 GPIO8D0 reset 0xFFFFFFFF — GPIO Write Privilege Control Register \#48
  [15:8] GPIO193WrPrivilegeOfMaster — GPIO193 Write Privilege of Master
  [7:0] GPIO192WrPrivilegeOfMaster — GPIO192 Write Privilege of Master
0x910 GPIO910 reset 0xFFFFFFFF — GPIO Read Privilege Control Register \#0
  [8n+7:8n] GPIO{n:03}ReadPrivilegeOfMaster (n=0..3)
0x914 GPIO914 reset 0xFFFFFFFF — GPIO Read Privilege Control Register \#1
  [8n-25:8n-32] GPIO{n:03}ReadPrivilegeOfMaster (n=4..7)
0x918 GPIO918 reset 0xFFFFFFFF — GPIO Read Privilege Control Register \#2
  [8n-57:8n-64] GPIO{n:03}ReadPrivilegeOfMaster (n=8..11)
0x91C GPIO91C reset 0xFFFFFFFF — GPIO Read Privilege Control Register \#3
  [8n-89:8n-96] GPIO{n:03}ReadPrivilegeOfMaster (n=12..15)
0x920 GPIO920 reset 0xFFFFFFFF — GPIO Read Privilege Control Register \#4
  [8n-121:8n-128] GPIO{n:03}ReadPrivilegeOfMaster (n=16..19)
0x924 GPIO924 reset 0xFFFFFFFF — GPIO Read Privilege Control Register \#5
  [8n-153:8n-160] GPIO{n:03}ReadPrivilegeOfMaster (n=20..23)
0x928 GPIO928 reset 0xFFFFFFFF — GPIO Read Privilege Control Register \#6
  [8n-185:8n-192] GPIO{n:03}ReadPrivilegeOfMaster (n=24..27)
0x92C GPIO92C reset 0xFFFFFFFF — GPIO Read Privilege Control Register \#7
  [8n-217:8n-224] GPIO{n:03}ReadPrivilegeOfMaster (n=28..31)
0x930 GPIO930 reset 0xFFFFFFFF — GPIO Read Privilege Control Register \#8
  [8n-249:8n-256] GPIO{n:03}ReadPrivilegeOfMaster (n=32..35)
0x934 GPIO934 reset 0xFFFFFFFF — GPIO Read Privilege Control Register \#9
  [8n-281:8n-288] GPIO{n:03}ReadPrivilegeOfMaster (n=36..39)
0x938 GPIO938 reset 0xFFFFFFFF — GPIO Read Privilege Control Register \#10
  [8n-313:8n-320] GPIO{n:03}ReadPrivilegeOfMaster (n=40..43)
0x93C GPIO93C reset 0xFFFFFFFF — GPIO Read Privilege Control Register \#11
  [8n-345:8n-352] GPIO{n:03}ReadPrivilegeOfMaster (n=44..47)
0x940 GPIO940 reset 0xFFFFFFFF — GPIO Read Privilege Control Register \#12
  [8n-377:8n-384] GPIO{n:03}ReadPrivilegeOfMaster (n=48..51)
0x944 GPIO944 reset 0xFFFFFFFF — GPIO Read Privilege Control Register \#13
  [8n-409:8n-416] GPIO{n:03}ReadPrivilegeOfMaster (n=52..55)
0x948 GPIO948 reset 0xFFFFFFFF — GPIO Read Privilege Control Register \#14
  [8n-441:8n-448] GPIO{n:03}ReadPrivilegeOfMaster (n=56..59)
0x94C GPIO94C reset 0xFFFFFFFF — GPIO Read Privilege Control Register \#15
  [8n-473:8n-480] GPIO{n:03}ReadPrivilegeOfMaster (n=60..63)
0x950 GPIO950 reset 0xFFFFFFFF — GPIO Read Privilege Control Register \#16
  [8n-505:8n-512] GPIO{n:03}ReadPrivilegeOfMaster (n=64..67)
0x954 GPIO954 reset 0xFFFFFFFF — GPIO Read Privilege Control Register \#17
  [8n-537:8n-544] GPIO{n:03}ReadPrivilegeOfMaster (n=68..71)
0x958 GPIO958 reset 0xFFFFFFFF — GPIO Read Privilege Control Register \#18
  [8n-569:8n-576] GPIO{n:03}ReadPrivilegeOfMaster (n=72..75)
0x95C GPIO95C reset 0xFFFFFFFF — GPIO Read Privilege Control Register \#19
  [8n-601:8n-608] GPIO{n:03}ReadPrivilegeOfMaster (n=76..79)
0x960 GPIO960 reset 0xFFFFFFFF — GPIO Read Privilege Control Register \#20
  [8n-633:8n-640] GPIO{n:03}ReadPrivilegeOfMaster (n=80..83)
0x964 GPIO964 reset 0xFFFFFFFF — GPIO Read Privilege Control Register \#21
  [8n-665:8n-672] GPIO{n:03}ReadPrivilegeOfMaster (n=84..87)
0x968 GPIO968 reset 0xFFFFFFFF — GPIO Read Privilege Control Register \#22
  [8n-697:8n-704] GPIO{n:03}ReadPrivilegeOfMaster (n=88..91)
0x96C GPIO96C reset 0xFFFFFFFF — GPIO Read Privilege Control Register \#23
  [8n-729:8n-736] GPIO{n:03}ReadPrivilegeOfMaster (n=92..95)
0x970 GPIO970 reset 0xFFFFFFFF — GPIO Read Privilege Control Register \#24
  [8n-761:8n-768] GPIO{n:03}ReadPrivilegeOfMaster (n=96..99)
0x974 GPIO974 reset 0xFFFFFFFF — GPIO Read Privilege Control Register \#25
  [8n-793:8n-800] GPIO{n}ReadPrivilegeOfMaster (n=100..103)
0x978 GPIO978 reset 0xFFFFFFFF — GPIO Read Privilege Control Register \#26
  [8n-825:8n-832] GPIO{n}ReadPrivilegeOfMaster (n=104..107)
0x97C GPIO97C reset 0xFFFFFFFF — GPIO Read Privilege Control Register \#27
  [8n-857:8n-864] GPIO{n}ReadPrivilegeOfMaster (n=108..111)
0x980 GPIO980 reset 0xFFFFFFFF — GPIO Read Privilege Control Register \#28
  [8n-889:8n-896] GPIO{n}ReadPrivilegeOfMaster (n=112..115)
0x984 GPIO984 reset 0xFFFFFFFF — GPIO Read Privilege Control Register \#29
  [8n-921:8n-928] GPIO{n}ReadPrivilegeOfMaster (n=116..119)
0x988 GPIO988 reset 0xFFFFFFFF — GPIO Read Privilege Control Register \#30
  [8n-953:8n-960] GPIO{n}ReadPrivilegeOfMaster (n=120..123)
0x98C GPIO98C reset 0xFFFFFFFF — GPIO Read Privilege Control Register \#31
  [8n-985:8n-992] GPIO{n}ReadPrivilegeOfMaster (n=124..127)
0x990 GPIO990 reset 0xFFFFFFFF — GPIO Read Privilege Control Register \#32
  [8n-1017:8n-1024] GPIO{n}ReadPrivilegeOfMaster (n=128..131)
0x994 GPIO994 reset 0xFFFFFFFF — GPIO Read Privilege Control Register \#33
  [8n-1049:8n-1056] GPIO{n}ReadPrivilegeOfMaster (n=132..135)
0x998 GPIO998 reset 0xFFFFFFFF — GPIO Read Privilege Control Register \#34
  [8n-1081:8n-1088] GPIO{n}ReadPrivilegeOfMaster (n=136..139)
0x99C GPIO99C reset 0xFFFFFFFF — GPIO Read Privilege Control Register \#35
  [8n-1113:8n-1120] GPIO{n}ReadPrivilegeOfMaster (n=140..143)
0x9A0 GPIO9A0 reset 0xFFFFFFFF — GPIO Read Privilege Control Register \#36
  [8n-1145:8n-1152] GPIO{n}ReadPrivilegeOfMaster (n=144..147)
0x9A4 GPIO9A4 reset 0xFFFFFFFF — GPIO Read Privilege Control Register \#37
  [8n-1177:8n-1184] GPIO{n}ReadPrivilegeOfMaster (n=148..151)
0x9A8 GPIO9A8 reset 0xFFFFFFFF — GPIO Read Privilege Control Register \#38
  [8n-1209:8n-1216] GPIO{n}ReadPrivilegeOfMaster (n=152..155)
0x9AC GPIO9AC reset 0xFFFFFFFF — GPIO Read Privilege Control Register \#39
  [8n-1241:8n-1248] GPIO{n}ReadPrivilegeOfMaster (n=156..159)
0x9B0 GPIO9B0 reset 0xFFFFFFFF — GPIO Read Privilege Control Register \#40
  [8n-1273:8n-1280] GPIO{n}ReadPrivilegeOfMaster (n=160..163)
0x9B4 GPIO9B4 reset 0xFFFFFFFF — GPIO Read Privilege Control Register \#41
  [8n-1305:8n-1312] GPIO{n}ReadPrivilegeOfMaster (n=164..167)
0x9B8 GPIO9B8 reset 0xFFFFFFFF — GPIO Read Privilege Control Register \#42
  [8n-1337:8n-1344] GPIO{n}ReadPrivilegeOfMaster (n=168..171)
0x9BC GPIO9BC reset 0xFFFFFFFF — GPIO Read Privilege Control Register \#43
  [8n-1369:8n-1376] GPIO{n}ReadPrivilegeOfMaster (n=172..175)
0x9C0 GPIO9C0 reset 0xFFFFFFFF — GPIO Read Privilege Control Register \#44
  [8n-1401:8n-1408] GPIO{n}ReadPrivilegeOfMaster (n=176..179)
0x9C4 GPIO9C4 reset 0xFFFFFFFF — GPIO Read Privilege Control Register \#45
  [8n-1433:8n-1440] GPIO{n}ReadPrivilegeOfMaster (n=180..183)
0x9C8 GPIO9C8 reset 0xFFFFFFFF — GPIO Read Privilege Control Register \#46
  [8n-1465:8n-1472] GPIO{n}ReadPrivilegeOfMaster (n=184..187)
0x9CC GPIO9CC reset 0xFFFFFFFF — GPIO Read Privilege Control Register \#47
  [8n-1497:8n-1504] GPIO{n}ReadPrivilegeOfMaster (n=188..191)
0x9D0 GPIO9D0 reset 0xFFFFFFFF — GPIO Read Privilege Control Register \#48
  [15:8] GPIO193ReadPrivilegeOfMaster, [7:0] GPIO192ReadPrivilegeOfMaster
0xA14 GPIOA14 reset 0x1F1F1F1F — GPIO Interrupt Target Control Register \#1
  [8n-25] GPIO{n:03}INTTargetWrProt (n=4..7) — GPIO{n:03} Interrupt Target Write Protection
  [8n-26] GPIO{n:03}INTTargetRstTolerance (n=4..7) — GPIO{n:03} Interrupt Target Reset Tolerance
    0=Interrupt_Target_Is_Reset_By_WDT; 1=Interrupt_Target_Is_NOT_Reset_By_WDT
  [8n-29] EnblGPIO{n:03}INTToSIO (n=4..7) — Enable GPIO{n:03} Interrupt To SIO
  [8n-30] EnblGPIO{n:03}INTToINT13020 (n=4..7) — Enable GPIO{n:03} Interrupt To INT#130_20
  [8n-31] EnblGPIO{n:03}INTToINT13019 (n=4..7) — Enable GPIO{n:03} Interrupt To INT#130_19
  [8n-32] EnblGPIO{n:03}INTToINT13018 (n=4..7) — Enable GPIO{n:03} Interrupt To INT#130_18
